AUTOSAR XML (schema 314)
package /ComponentType
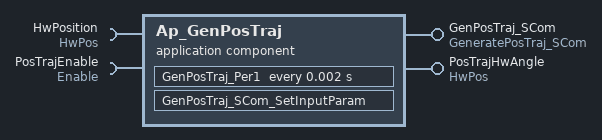
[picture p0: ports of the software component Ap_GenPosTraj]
  application software component type Ap_GenPosTraj
    provide port GenPosTraj_SCom: server-com-spec{operation=SetInputParam, queue-length=1}, provided-interface=GeneratePosTraj_SCom
    provide port PosTrajHwAngle: unqueued-sender-com-spec{data-element=HwDeg_f32, can-invalidate=false, init-value=D_ZERO_ULS_F32}, provided-interface=HwPos
    require port HwPosition: unqueued-receiver-com-spec{data-element=HwDeg_f32, init-value=D_ZERO_ULS_F32}, required-interface=HwPos
    require port PosTrajEnable: unqueued-receiver-com-spec{data-element=Cnt_lgc, init-value=D_FALSE_CNT_LGC}, required-interface=Enable
  internal behavior Ap_GenPosTraj_InternalBehavior: component=Ap_GenPosTraj
    timing event TMT_GenPosTraj_Per1: start-on-event=GenPosTraj_Per1, period=0.002
    operation invoked event OIT_GenPosTraj_SCom_SetInputParam_GenPosTraj_SCom_SetInputParam: start-on-event=GenPosTraj_SCom_SetInputParam, operation=GenPosTraj_SCom.SetInputParam
    port-api-options:
      enable-take-address=false, indirect-api=false, port=GenPosTraj_SCom
      enable-take-address=false, indirect-api=false, port=HwPosition
      enable-take-address=false, indirect-api=false, port=PosTrajEnable
      enable-take-address=false, indirect-api=false, port=PosTrajHwAngle
    runnable GenPosTraj_Per1
      data read access READ_HwPosition_HwDeg_f32: data-element=HwPosition.HwDeg_f32
      data read access READ_PosTrajEnable_Cnt_lgc: data-element=PosTrajEnable.Cnt_lgc
      data write access WRITE_PosTrajHwAngle_HwDeg_f32: data-element=PosTrajHwAngle.HwDeg_f32
    runnable GenPosTraj_SCom_SetInputParam
  swc implementation Ap_GenPosTraj_Implementation: behavior=Ap_GenPosTraj_InternalBehavior
    code-descriptors:
      code Code: type=SRC
